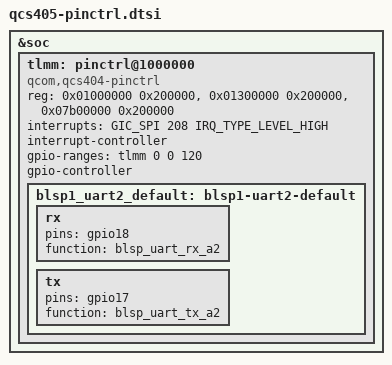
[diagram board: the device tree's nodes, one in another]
&soc {
	tlmm: pinctrl@1000000 {
		compatible = "qcom,qcs404-pinctrl";
		reg = <0x01000000 0x200000>,
		      <0x01300000 0x200000>,
		      <0x07b00000 0x200000>;
		reg-names = "south", "north", "east";
		interrupts = <GIC_SPI 208 IRQ_TYPE_LEVEL_HIGH>;
		interrupt-controller;
		#interrupt-cells = <2>;
		gpio-ranges = <&tlmm 0 0 120>;
		gpio-controller;
		#gpio-cells = <2>;

		blsp1_uart2_default: blsp1-uart2-default {
			rx {
				pins = "gpio18";
				function = "blsp_uart_rx_a2";
			};

			tx {
				pins = "gpio17";
				function = "blsp_uart_tx_a2";
			};
		};

	};
};
